# STM32L4x6 register map
File version: 1.5
CPU: CM4 r1p0, little endian, no MPU, FPU, 3 interrupt priority bits
Registers are 32-bit, read-write, reset 0x0 unless marked. A register's access mark holds for its fields unless they carry their own. Offsets are from the block's base; [hi:lo] are bit positions; {n}, {i} and the like mark numbered series.

## RNG — Random number generator
Base 0x50060800
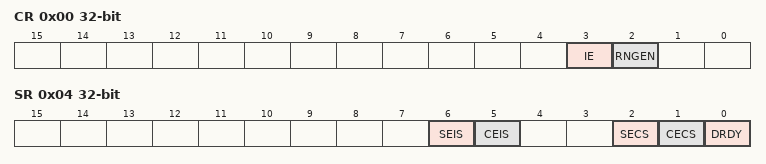
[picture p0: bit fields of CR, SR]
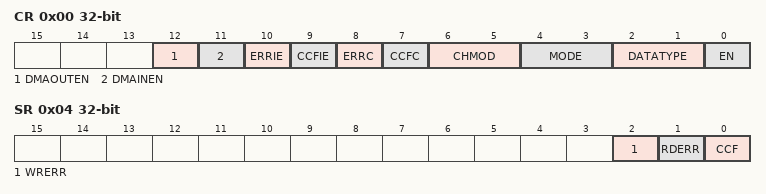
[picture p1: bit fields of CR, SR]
0x00 CR — control register
  [3] IE — Interrupt enable
  [2] RNGEN — Random number generator enable
0x04 SR access per field — status register
  [6] SEIS rw — Seed error interrupt status
  [5] CEIS rw — Clock error interrupt status
  [2] SECS ro — Seed error current status
  [1] CECS ro — Clock error current status
  [0] DRDY ro — Data ready
0x08 DR ro — data register
  [31:0] RNDATA — Random data

## AES — Advanced encryption standard hardware accelerator
Base 0x50060000
0x00 CR — control register
  [12] DMAOUTEN — Enable DMA management of data output phase
  [11] DMAINEN — Enable DMA management of data input phase
  [10] ERRIE — Error interrupt enable
  [9] CCFIE — CCF flag interrupt enable
  [8] ERRC — Error clear
  [7] CCFC — Computation Complete Flag Clear
  [6:5] CHMOD — AES chaining mode
  [4:3] MODE — AES operating mode
  [2:1] DATATYPE — Data type selection (for data in and data out to/from the cryptographic block)
  [0] EN — AES enable
0x04 SR ro — status register
  [2] WRERR — Write error flag
  [1] RDERR — Read error flag
  [0] CCF — Computation complete flag
0x08 DINR — data input register
  [31:0] AES_DINR — Data Input Register
0x0C DOUTR ro — data output register
  [31:0] AES_DOUTR — Data output register
0x10 KEYR0 — key register 0
  [31:0] AES_KEYR0 — Data Output Register (LSB key [31:0])
0x14 KEYR1 — key register 1
  [31:0] AES_KEYR1 — AES key register (key [63:32])
0x18 KEYR2 — key register 2
  [31:0] AES_KEYR2 — AES key register (key [95:64])
0x1C KEYR3 — key register 3
  [31:0] AES_KEYR3 — AES key register (MSB key [127:96])
0x20 IVR0 — initialization vector register 0
  [31:0] AES_IVR0 — initialization vector register (LSB IVR [31:0])
0x24 IVR1 — initialization vector register 1
  [31:0] AES_IVR1 — Initialization Vector Register (IVR [63:32])
0x28 IVR2 — initialization vector register 2
  [31:0] AES_IVR2 — Initialization Vector Register (IVR [95:64])
0x2C IVR3 — initialization vector register 3
  [31:0] AES_IVR3 — Initialization Vector Register (MSB IVR [127:96])

## ADC1 — Analog-to-Digital Converter
Base 0x50040000
Same registers: ADC2 0x50040100, ADC3 0x50040200
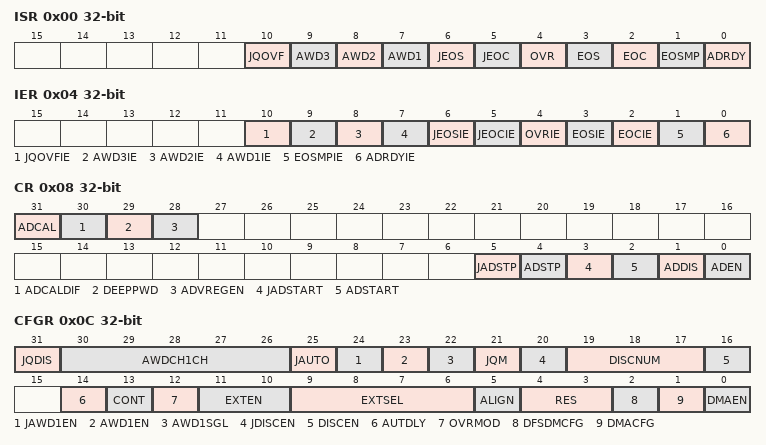
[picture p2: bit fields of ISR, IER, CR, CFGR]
0x00 ISR — interrupt and status register
  [10] JQOVF, [9] AWD3, [8] AWD2, [7] AWD1, [6] JEOS, [5] JEOC, [4] OVR, [3] EOS, [2] EOC, [1] EOSMP, [0] ADRDY
0x04 IER — interrupt enable register
  [10] JQOVFIE, [9] AWD3IE, [8] AWD2IE, [7] AWD1IE, [6] JEOSIE, [5] JEOCIE, [4] OVRIE, [3] EOSIE, [2] EOCIE, [1] EOSMPIE, [0] ADRDYIE
0x08 CR — control register
  [31] ADCAL, [30] ADCALDIF, [29] DEEPPWD, [28] ADVREGEN, [5] JADSTP, [4] ADSTP, [3] JADSTART, [2] ADSTART, [1] ADDIS, [0] ADEN
0x0C CFGR — configuration register
  [31] JQDIS — Injected Queue disable
  [30:26] AWDCH1CH
  [25] JAUTO
  [24] JAWD1EN
  [23] AWD1EN
  [22] AWD1SGL
  [21] JQM
  [20] JDISCEN
  [19:17] DISCNUM
  [16] DISCEN
  [14] AUTDLY
  [13] CONT
  [12] OVRMOD
  [11:10] EXTEN
  [9:6] EXTSEL
  [5] ALIGN
  [4:3] RES
  [2] DFSDMCFG
  [1] DMACFG
  [0] DMAEN
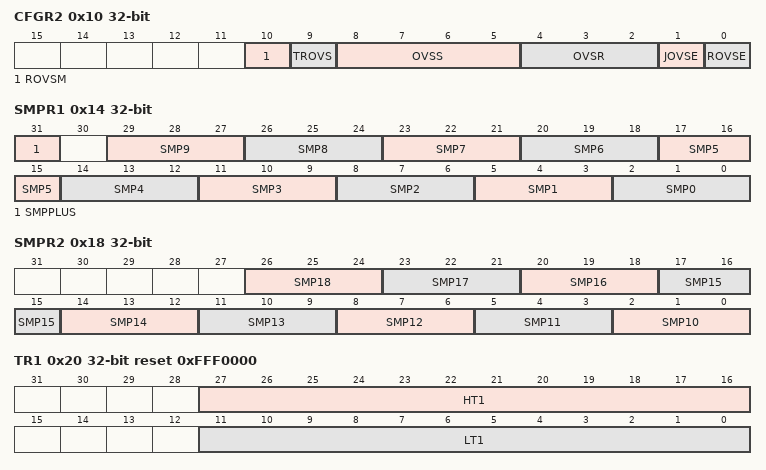
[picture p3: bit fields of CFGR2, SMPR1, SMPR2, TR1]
0x10 CFGR2 — configuration register
  [10] ROVSM — EXTEN
  [9] TROVS — Triggered Regular Oversampling
  [8:5] OVSS — ALIGN
  [4:2] OVSR — RES
  [1] JOVSE — DMACFG
  [0] ROVSE — DMAEN
0x14 SMPR1 — sample time register 1
  [31] SMPPLUS — Addition of one clock cycle to the sampling time
  [3n+2:3n] SMP{n} (n=0..9)
0x18 SMPR2 — sample time register 2
  [3n-28:3n-30] SMP{n} (n=10..18)
0x20 TR1 reset 0xFFF0000 — watchdog threshold register 1
  [27:16] HT1, [11:0] LT1
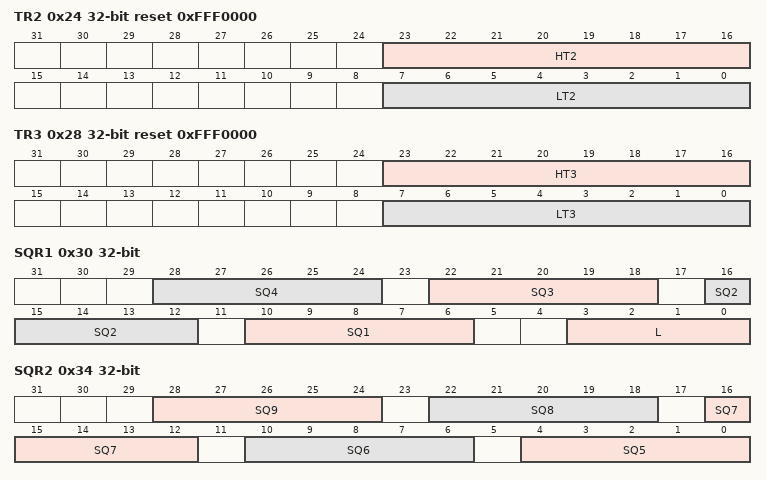
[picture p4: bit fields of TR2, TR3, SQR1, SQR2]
0x24 TR2 reset 0xFFF0000 — watchdog threshold register
  [23:16] HT2, [7:0] LT2
0x28 TR3 reset 0xFFF0000 — watchdog threshold register 3
  [23:16] HT3, [7:0] LT3
0x30 SQR1 — regular sequence register 1
  [6n+4:6n] SQ{n} (n=1..4)
  [3:0] L — Regular channel sequence length
0x34 SQR2 — regular sequence register 2
  [6n-26:6n-30] SQ{n} (n=5..9)
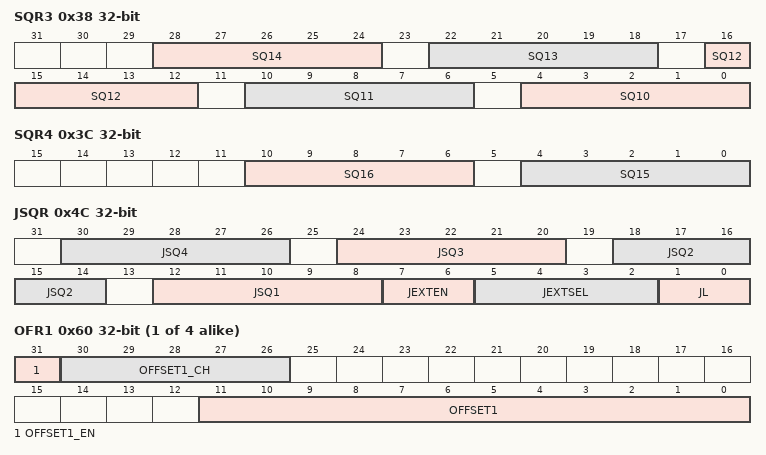
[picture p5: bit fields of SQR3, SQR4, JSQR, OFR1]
0x38 SQR3 — regular sequence register 3
  [6n-56:6n-60] SQ{n} (n=10..14)
0x3C SQR4 — regular sequence register 4
  [10:6] SQ16, [4:0] SQ15
0x40 DR ro — regular Data Register
  [15:0] RDATA — Regular Data converted
0x4C JSQR — injected sequence register
  [6n+6:6n+2] JSQ{n} (n=1..4), [7:6] JEXTEN, [5:2] JEXTSEL, [1:0] JL
{0x5C+4i} OFR{i} (i=1..4) — offset register {i}
  [31] OFFSET{i}_EN, [30:26] OFFSET{i}_CH, [11:0] OFFSET{i}
{0x7C+4i} JDR{i} ro (i=1..4) — injected data register {i}
  [15:0] JDATA{i}
0xA0 AWD2CR — Analog Watchdog 2 Configuration Register
  [18:0] AWD2CH
0xA4 AWD3CR — Analog Watchdog 3 Configuration Register
  [18:0] AWD3CH
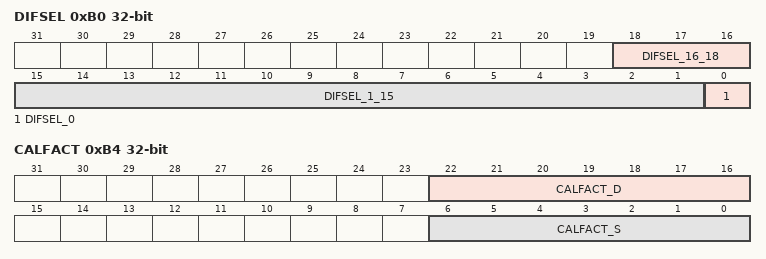
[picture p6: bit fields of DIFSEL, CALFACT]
0xB0 DIFSEL access per field — Differential Mode Selection Register 2
  [18:16] DIFSEL_16_18 ro — Differential mode for channels 18 to 16
  [15:1] DIFSEL_1_15 rw — Differential mode for channels 15 to 1
  [0] DIFSEL_0 ro — Differential mode for channels 0
0xB4 CALFACT — Calibration Factors
  [22:16] CALFACT_D, [6:0] CALFACT_S
